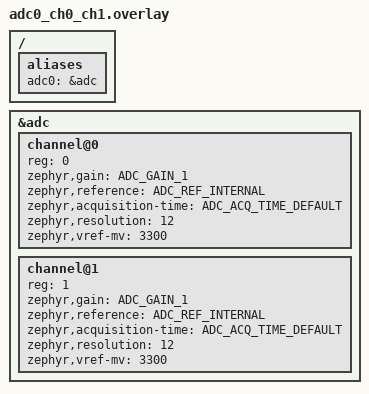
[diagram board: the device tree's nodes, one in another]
/* SPDX-License-Identifier: Apache-2.0 OR MIT */
/*
 * samples/drivers/adc/adc_sequence reads every channel of the adc0 alias:
 * the RP2's ADC inputs 0 (GP26) and 1 (GP27), 12 bits against the 3.3 V
 * reference, as the sample's adc_dt sibling's rpi_pico overlay sets input 0.
 */
/ {
	aliases {
		adc0 = &adc;
	};
};

&adc {
	#address-cells = <1>;
	#size-cells = <0>;
	status = "okay";

	channel@0 {
		reg = <0>;
		zephyr,gain = "ADC_GAIN_1";
		zephyr,reference = "ADC_REF_INTERNAL";
		zephyr,acquisition-time = <ADC_ACQ_TIME_DEFAULT>;
		zephyr,resolution = <12>;
		zephyr,vref-mv = <3300>;
	};

	channel@1 {
		reg = <1>;
		zephyr,gain = "ADC_GAIN_1";
		zephyr,reference = "ADC_REF_INTERNAL";
		zephyr,acquisition-time = <ADC_ACQ_TIME_DEFAULT>;
		zephyr,resolution = <12>;
		zephyr,vref-mv = <3300>;
	};
};
